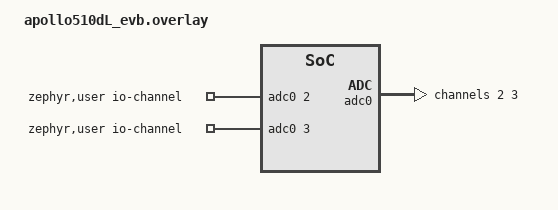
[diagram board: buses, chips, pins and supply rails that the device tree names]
/*
 * Copyright (c) 2025 Ambiq Micro Inc.
 *
 * SPDX-License-Identifier: Apache-2.0
 */
/ {
	zephyr,user {
		io-channels = <&adc0 2>, <&adc0 3>;
	};
};

&adc0 {
	status = "okay";
	interrupt-parent = <&nvic>;
	interrupts = <19 0>;
	dma-mode;
	dma-buffer-location = "SRAM_NO_CACHE";
	dma-buffer-size = <128>;
	#address-cells = <1>;
	#size-cells = <0>;

	channel@2 {
		reg = <2>;
		zephyr,gain = "ADC_GAIN_1";
		zephyr,reference = "ADC_REF_INTERNAL";
		zephyr,acquisition-time = <ADC_ACQ_TIME_DEFAULT>;
		zephyr,resolution = <12>;
	};

	channel@3 {
		reg = <3>;
		zephyr,gain = "ADC_GAIN_1";
		zephyr,reference = "ADC_REF_INTERNAL";
		zephyr,acquisition-time = <ADC_ACQ_TIME_DEFAULT>;
		zephyr,resolution = <12>;
	};
};
